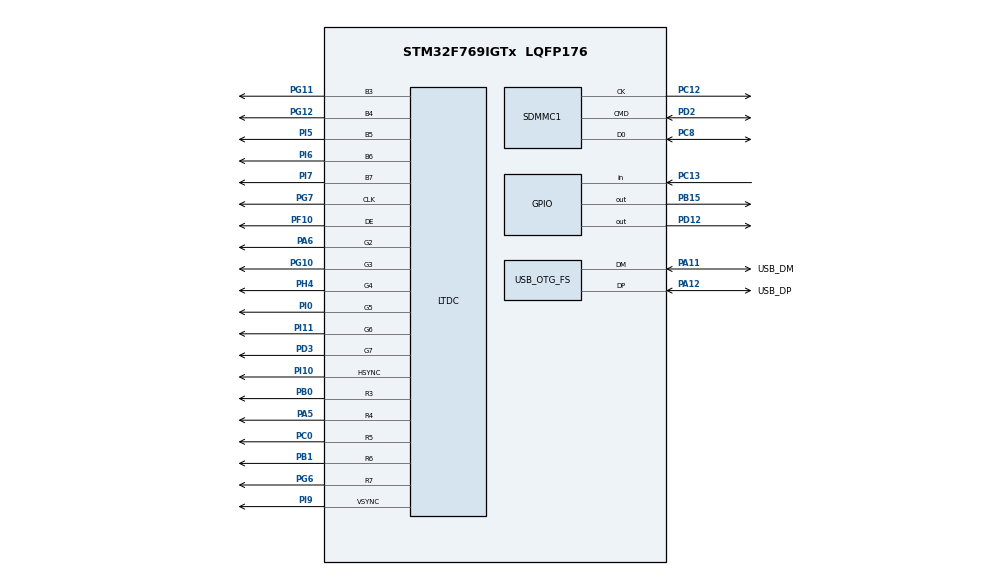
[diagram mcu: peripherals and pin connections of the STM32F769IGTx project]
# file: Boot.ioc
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Mcu.Family=STM32F7
PA6.Mode=RGB565
RCC.CortexFreq_Value=216000000
PG6.Signal=LTDC_R7
VP_FATFS_VS_SDIO.Mode=SDIO
PC12.Signal=SDMMC1_CK
RCC.SYSCLKSourceVirtual=RCC_SYSCLKSOURCE_PLLCLK
PA11.Mode=Device_Only
PC14/OSC32_IN.Mode=LSE-External-Oscillator
PB15.Signal=GPIO_Output
PI5.Mode=RGB565
PG6.Mode=RGB565
PB15.PinState=GPIO_PIN_RESET
PG11.Signal=LTDC_B3
RCC.SYSCLKSource=RCC_SYSCLKSOURCE_PLLCLK
ProjectManager.StackSize=0x400
PI11.Mode=RGB565
PA12.Signal=USB_OTG_FS_DP
LTDC.Blue=1
PH0/OSC_IN.Mode=HSE-External-Oscillator
RCC.HCLKFreq_Value=216000000
RCC.APB2TimFreq_Value=216000000
PH1/OSC_OUT.Signal=RCC_OSC_OUT
PI9.Mode=RGB565
RCC.AHBFreq_Value=216000000
RCC.HSE_VALUE=25000000
RCC.PLLMUL=RCC_PLL_MUL9
PI5.Signal=LTDC_B5
PI6.Signal=LTDC_B6
PI0.Signal=LTDC_G5
PC13.GPIO_PuPd=GPIO_NOPULL
DMA2D.ColorMode=DMA2D_OUTPUT_RGB565
PD3.Mode=RGB565
PH1/OSC_OUT.Mode=HSE-External-Oscillator
Mcu.Package=LQFP176
RCC.SDMMCClockSelection=RCC_SDMMC1CLKSOURCE_CLK48
PB1.Signal=LTDC_R6
PA6.Signal=LTDC_G2
PC14/OSC32_IN.Signal=RCC_OSC32_IN
PD12.Signal=GPIO_Output
USB_OTG_FS.VirtualMode=Device_Only
RCC.APB2CLKDivider=RCC_HCLK_DIV2
PI7.Mode=RGB565
RCC.APB1TimFreq_Value=108000000
VP_DMA2D_VS_DMA2D.Mode=DMA2D_Activate
PF10.Mode=RGB565
PI11.Signal=LTDC_G6
PA5.Mode=RGB565
PG12.Signal=LTDC_B4
PD12.PinState=GPIO_PIN_RESET
PG7.Signal=LTDC_CLK
PC13.Signal=GPIO_Input
PD3.Signal=LTDC_G7
PI10.Mode=RGB565
PC8.Signal=SDMMC1_D0
PG10.Mode=RGB565
PA11.GPIO_Label=USB_DM
PI10.Signal=LTDC_HSYNC
PC0.Signal=LTDC_R5
RCC.APB1CLKDivider=RCC_HCLK_DIV4
PA12.GPIO_Label=USB_DP
PG10.Signal=LTDC_G3
PC0.Mode=RGB565
PH4.Signal=LTDC_G4
ProjectManager.TargetToolchain=STM32CubeIDE
PI0.Mode=RGB565
PI6.Mode=RGB565
RCC.USBFreq_Value=48000000
PG7.Mode=RGB565
PD2.Mode=SD_1_bit
PA5.Signal=LTDC_R4
PC12.Mode=SD_1_bit
PB0.Mode=RGB565
board=NUCLEO-F746ZG
PG12.Mode=RGB565
RCC.VCOOutputFreq_Value=432000000
PI9.Signal=LTDC_VSYNC
PI7.Signal=LTDC_B7
PH0/OSC_IN.Signal=RCC_OSC_IN
RCC.APB2Freq_Value=108000000
RCC.PRESCALERUSB=RCC_USBCLKSOURCE_PLL_DIV1_5
PF10.Signal=LTDC_DE
USB_OTG_FS.Sof_enable=ENABLE
Mcu.Name=STM32F769IGTx
PH4.Mode=RGB565
PC8.Mode=SD_1_bit
RCC.48MHZClocksFreq_Value=24000000
RCC.SYSCLKFreq_VALUE=216000000
PA12.Mode=Device_Only
PC15/OSC32_OUT.Mode=LSE-External-Oscillator
PG11.Mode=RGB565
PA11.Signal=USB_OTG_FS_DM
ProjectManager.HeapSize=0x200
PB1.Mode=RGB565
RCC.HSI_VALUE=16000000
PH0/OSC_IN.GPIO_Label=MCO [STM32F103CBT6_PA8]
RCC.PLLQ=9
NVIC.PriorityGroup=NVIC_PRIORITYGROUP_4
RCC.PLLM=25
RCC.PLLN=432
PC15/OSC32_OUT.Signal=RCC_OSC32_OUT
PD2.Signal=SDMMC1_CMD
RCC.APB1Freq_Value=54000000
PB0.Signal=LTDC_R3

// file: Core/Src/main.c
/* USER CODE BEGIN Header */
/**
  ******************************************************************************
  * @file           : main.c
  * @brief          : Main program body
  ******************************************************************************
  * @attention
  *
  * <h2><center>&copy; Copyright (c) 2020 STMicroelectronics.
  * All rights reserved.</center></h2>
  *
  * This software component is licensed by ST under BSD 3-Clause license,
  * the "License"; You may not use this file except in compliance with the
  * License. You may obtain a copy of the License at:
  *                        opensource.org/licenses/BSD-3-Clause
  *
  ******************************************************************************
  */
/* USER CODE END Header */
#include "main.h"
#include "dma2d.h"
#include "fatfs.h"
#include "ltdc.h"
#include "sdmmc.h"
#include "gpio.h"

void SystemClock_Config(void);
/* USER CODE BEGIN PFP */
/**
  * @brief  Clock Config.
  * @param  hltdc: LTDC handle
  * @param  Params
  * @note   This API is called by BSP_LCD_Init()
  *         Being __weak it can be overwritten by the application
  * @retval None
  */
__weak void BSP_LCD_ClockConfig(LTDC_HandleTypeDef *hltdc, void *Params)
{
  static RCC_PeriphCLKInitTypeDef  periph_clk_init_struct;

  /* RK043FN48H LCD clock configuration */
  /* PLLSAI_VCO Input = HSE_VALUE/PLL_M = 1 Mhz */
  /* PLLSAI_VCO Output = PLLSAI_VCO Input * PLLSAIN = 192 Mhz */
  /* PLLLCDCLK = PLLSAI_VCO Output/PLLSAIR = 192/5 = 38.4 Mhz */
  /* LTDC clock frequency = PLLLCDCLK / LTDC_PLLSAI_DIVR_4 = 38.4/4 = 9.6Mhz */
  periph_clk_init_struct.PeriphClockSelection = RCC_PERIPHCLK_LTDC;
  periph_clk_init_struct.PLLSAI.PLLSAIN = 200;
  periph_clk_init_struct.PLLSAI.PLLSAIR = 5;
  periph_clk_init_struct.PLLSAIDivR = RCC_PLLSAIDIVR_4;
  HAL_RCCEx_PeriphCLKConfig(&periph_clk_init_struct);
}
/* USER CODE END 0 */

int main(void)
{

  /* MCU Configuration--------------------------------------------------------*/

  /* Reset of all peripherals, Initializes the Flash interface and the Systick. */
  HAL_Init();

  /* Configure the system clock */
  SystemClock_Config();

  /* Initialize all configured peripherals */
  MX_GPIO_Init();
  MX_SDMMC1_SD_Init();
  MX_FATFS_Init();
  MX_LTDC_Init();
  MX_DMA2D_Init();
  /* USER CODE BEGIN 2 */
  /* Initialize the bootloader application. */
  AppInit();
  /* USER CODE END 2 */

  /* Infinite loop */
  /* USER CODE BEGIN WHILE */
  while (1)
  {
    /* Run the bootloader application. */
    AppTask();
    /* USER CODE END WHILE */

  }
}

void SystemClock_Config(void)
{
  LL_FLASH_SetLatency(LL_FLASH_LATENCY_7);
  while(LL_FLASH_GetLatency()!= LL_FLASH_LATENCY_7)
  {
  }
  LL_PWR_SetRegulVoltageScaling(LL_PWR_REGU_VOLTAGE_SCALE1);
  LL_PWR_EnableOverDriveMode();
  LL_RCC_HSE_Enable();

   /* Wait till HSE is ready */
  while(LL_RCC_HSE_IsReady() != 1)
  {

  }
  LL_RCC_PLL_ConfigDomain_SYS(LL_RCC_PLLSOURCE_HSE, LL_RCC_PLLM_DIV_25, 432, LL_RCC_PLLP_DIV_2);
  LL_RCC_PLL_ConfigDomain_48M(LL_RCC_PLLSOURCE_HSE, LL_RCC_PLLM_DIV_25, 432, LL_RCC_PLLQ_DIV_9);
  LL_RCC_PLLSAI_ConfigDomain_LTDC(LL_RCC_PLLSOURCE_HSE, LL_RCC_PLLM_DIV_25, 192, LL_RCC_PLLSAIR_DIV_2, LL_RCC_PLLSAIDIVR_DIV_2);
  LL_RCC_PLL_Enable();

   /* Wait till PLL is ready */
  while(LL_RCC_PLL_IsReady() != 1)
  {

  }
  LL_RCC_PLLSAI_Enable();

   /* Wait till PLL is ready */
  while(LL_RCC_PLLSAI_IsReady() != 1)
  {

  }
  LL_RCC_SetAHBPrescaler(LL_RCC_SYSCLK_DIV_1);
  LL_RCC_SetAPB1Prescaler(LL_RCC_APB1_DIV_4);
  LL_RCC_SetAPB2Prescaler(LL_RCC_APB2_DIV_2);
  LL_RCC_SetSysClkSource(LL_RCC_SYS_CLKSOURCE_PLL);

   /* Wait till System clock is ready */
  while(LL_RCC_GetSysClkSource() != LL_RCC_SYS_CLKSOURCE_STATUS_PLL)
  {

  }
  LL_SetSystemCoreClock(216000000);

   /* Update the time base */
  if (HAL_InitTick (TICK_INT_PRIORITY) != HAL_OK)
  {
    Error_Handler();
  }
  LL_RCC_SetCK48MClockSource(LL_RCC_CK48M_CLKSOURCE_PLL);
  LL_RCC_SetUSBClockSource(LL_RCC_USB_CLKSOURCE_PLL);
  LL_RCC_SetSDMMCClockSource(LL_RCC_SDMMC1_CLKSOURCE_PLL48CLK);

  BSP_LCD_ClockConfig(&hltdc,NULL);
}

void Error_Handler(void)
{
}

/************************ (C) COPYRIGHT STMicroelectronics *****END OF FILE****/
